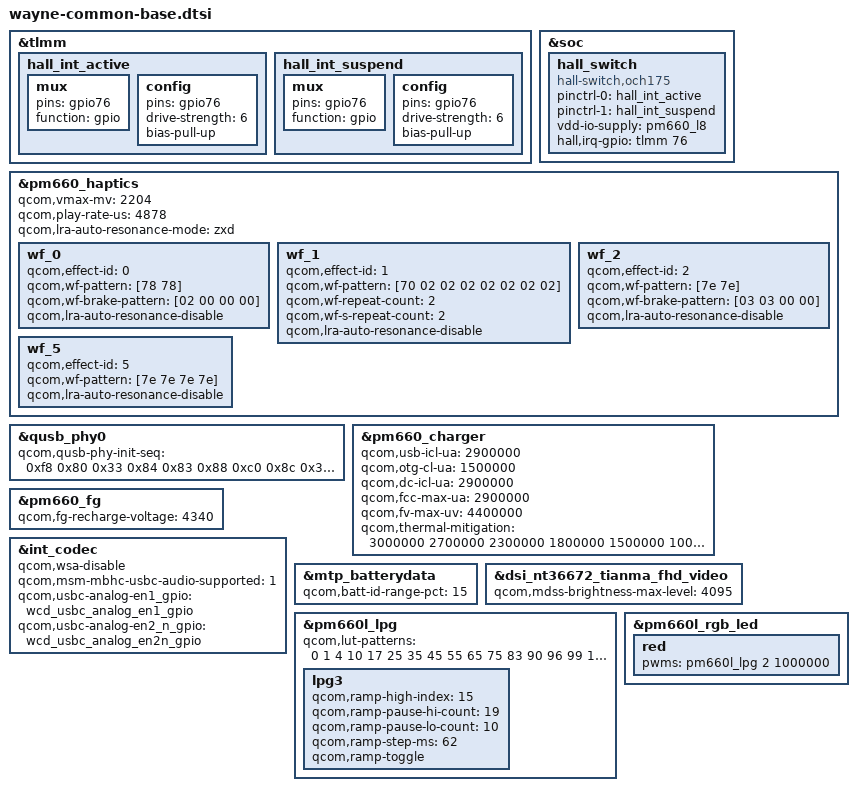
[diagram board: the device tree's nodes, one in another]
// SPDX-License-Identifier: GPL-2.0-only

#include "wayne-camera-sensor-mtp.dtsi"

/* Common between jasmine and wayne */
&tlmm {
	hall_int_active:hall_int_active {
		mux {
			pins = "gpio76";
			function = "gpio";
		};

		config {
			pins = "gpio76";
			drive-strength = <6>;
			bias-pull-up;
		};
	};

	hall_int_suspend: hall_int_suspend {
		mux {
			pins = "gpio76";
			function = "gpio";
		};

		config {
			pins = "gpio76";
			drive-strength = <6>;
			bias-pull-up;
		};
	};
};

&soc {
	hall_switch {
		compatible = "hall-switch,och175";
		pinctrl-names = "hall_active","hall_suspend";
		pinctrl-0 = <&hall_int_active>;
		pinctrl-1 = <&hall_int_suspend>;
		vdd-io-supply= <&pm660_l8>;
		interrupt-names = "hall_irq";
		hall,irq-gpio = <&tlmm 76 0x0>;
	};
};

&pm660_haptics {
	qcom,vmax-mv = <2204>;
	qcom,play-rate-us = <4878>;
	qcom,lra-auto-resonance-mode = "zxd";

	/delete-node/ wf_0;
	/delete-node/ wf_1;
	/delete-node/ wf_2;
	/delete-node/ wf_3;
	/delete-node/ wf_4;
	/delete-node/ wf_5;

	wf_0 {
		/* CLICK */
		qcom,effect-id = <0>;
		qcom,wf-pattern = [78 78];
		qcom,wf-brake-pattern = [02 00 00 00];
		qcom,lra-auto-resonance-disable;
	};
	wf_1 {
		/* DOUBLE CLICK */
		qcom,effect-id = <1>;
		qcom,wf-pattern = [70 02 02 02 02 02 02 02];
		qcom,wf-repeat-count = <2>;
		qcom,wf-s-repeat-count = <2>;
		qcom,lra-auto-resonance-disable;
	};
	wf_2 {
		/* TICK */
		qcom,effect-id = <2>;
		qcom,wf-pattern = [7e 7e];
		qcom,wf-brake-pattern = [03 03 00 00];
		qcom,lra-auto-resonance-disable;
	};
	wf_5 {
		/* HEAVY CLICK */
		qcom,effect-id = <5>;
		qcom,wf-pattern = [7e 7e 7e 7e];
		qcom,lra-auto-resonance-disable;
	};
};

/* sdm660-common.dtsi diff wayne - whyred/tulip */
&qusb_phy0 {
	qcom,qusb-phy-init-seq = <
		0xf8 0x80
		0x33 0x84
		0x83 0x88
		0xc0 0x8c
		0x30 0x08
		0x79 0x0c
		0x21 0x10
		0x14 0x9c
		0x9f 0x1c
		0x00 0x18
	>;
};

&pm660_charger {
	qcom,usb-icl-ua = <2900000>;
	qcom,otg-cl-ua = <1500000>;
	qcom,dc-icl-ua = <2900000>;
	qcom,fcc-max-ua = <2900000>;
	qcom,fv-max-uv = <4400000>;
	qcom,thermal-mitigation = <3000000 2700000 2300000 1800000 1500000 1000000 500000>;
};

&pm660_fg {
	qcom,fg-recharge-voltage = <4340>;
};

/* msm-audio.dtsi wayne specific diff */
&int_codec {
	qcom,wsa-disable;
	/delete-property/ qcom,msm-micbias2-ext-cap;
	qcom,msm-mbhc-usbc-audio-supported = <1>;
	qcom,usbc-analog-en1_gpio = <&wcd_usbc_analog_en1_gpio>;
	qcom,usbc-analog-en2_n_gpio = <&wcd_usbc_analog_en2n_gpio>;
};

/* sdm660-mtp.dtsi wayne specific diff */
&mtp_batterydata {
	qcom,batt-id-range-pct = <15>;
	#include "fg-gen3-batterydata-l8866sun-3000mah.dtsi"
	#include "fg-gen3-batterydata-l8866cos-3000mah.dtsi"
	#include "fg-gen3-batterydata-l8866default-3000mah.dtsi"
};

&dsi_nt36672_tianma_fhd_video {
	qcom,mdss-brightness-max-level = <4095>;
};

&pm660l_lpg {
	qcom,lut-patterns = <0 1 4 10 17 25 35 45 55
			     65 75 83 90 96 99 100>;

	lpg3 {
		qcom,ramp-high-index = <15>;
		qcom,ramp-pause-hi-count = <19>;
		qcom,ramp-pause-lo-count = <10>;
		qcom,ramp-step-ms = <62>;
		qcom,ramp-toggle;
	};
};

&pm660l_rgb_led {
	red {
		pwms = <&pm660l_lpg 2 1000000>;
	};

	/delete-node/ green;
	/delete-node/ blue;
};
